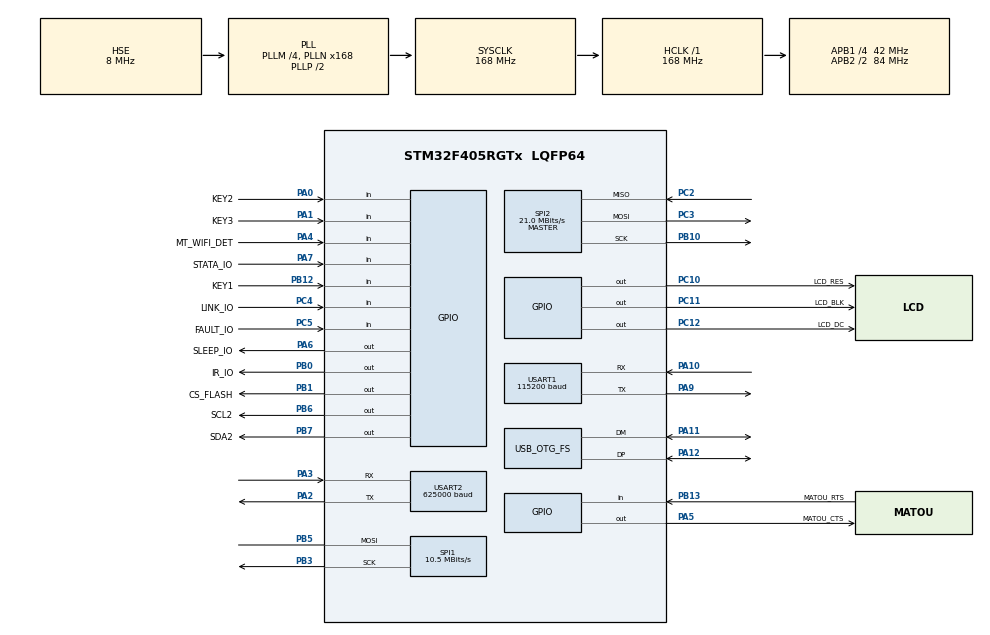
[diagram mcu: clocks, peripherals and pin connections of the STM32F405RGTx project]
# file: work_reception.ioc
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Dma.Request0=USART1_TX
Dma.Request1=USART2_TX
Dma.USART1_TX.0.Direction=DMA_MEMORY_TO_PERIPH
Dma.USART1_TX.0.FIFOMode=DMA_FIFOMODE_DISABLE
Dma.USART1_TX.0.Instance=DMA2_Stream7
Dma.USART1_TX.0.MemDataAlignment=DMA_MDATAALIGN_BYTE
Dma.USART1_TX.0.MemInc=DMA_MINC_ENABLE
Dma.USART1_TX.0.Mode=DMA_NORMAL
Dma.USART1_TX.0.PeriphDataAlignment=DMA_PDATAALIGN_BYTE
Dma.USART1_TX.0.PeriphInc=DMA_PINC_DISABLE
Dma.USART1_TX.0.Priority=DMA_PRIORITY_HIGH
Dma.USART2_TX.1.Direction=DMA_MEMORY_TO_PERIPH
Dma.USART2_TX.1.FIFOMode=DMA_FIFOMODE_DISABLE
Dma.USART2_TX.1.Instance=DMA1_Stream6
Dma.USART2_TX.1.MemDataAlignment=DMA_MDATAALIGN_BYTE
Dma.USART2_TX.1.MemInc=DMA_MINC_ENABLE
Dma.USART2_TX.1.Mode=DMA_NORMAL
Dma.USART2_TX.1.PeriphDataAlignment=DMA_PDATAALIGN_BYTE
Dma.USART2_TX.1.PeriphInc=DMA_PINC_DISABLE
Dma.USART2_TX.1.Priority=DMA_PRIORITY_LOW
FREERTOS.Tasks01=defaultTask,0,5000,StartDefaultTask,Default,NULL,Dynamic,NULL,NULL;FramSaveTask,-3,128,framSaveTaskFun,Default,NULL,Dynamic,NULL,NULL;CommunicationTa,-3,128,communicationTaskFun,Default,NULL,Dynamic,NULL,NULL
FREERTOS.configTOTAL_HEAP_SIZE=30000
Mcu.Family=STM32F4
Mcu.Name=STM32F405RGTx
Mcu.Package=LQFP64
NVIC.DMA1_Stream6_IRQn=true\:5\:0\:false\:false\:true\:true\:false\:true\:true
NVIC.DMA2_Stream7_IRQn=true\:5\:0\:false\:false\:true\:true\:false\:true\:true
NVIC.OTG_FS_IRQn=true\:5\:0\:false\:false\:true\:true\:true\:true\:true
NVIC.PriorityGroup=NVIC_PRIORITYGROUP_4
NVIC.RTC_Alarm_IRQn=true\:5\:0\:false\:false\:true\:true\:true\:true\:true
NVIC.TIM1_UP_TIM10_IRQn=true\:5\:0\:false\:false\:true\:true\:true\:true\:true
NVIC.TIM4_IRQn=true\:5\:0\:false\:false\:true\:true\:true\:true\:true
NVIC.TIM6_DAC_IRQn=true\:5\:0\:true\:false\:true\:true\:true\:true\:true
NVIC.TIM7_IRQn=true\:5\:0\:true\:false\:true\:true\:true\:true\:true
NVIC.TIM8_TRG_COM_TIM14_IRQn=true\:15\:0\:false\:false\:true\:false\:false\:true\:true
NVIC.TimeBase=TIM8_TRG_COM_TIM14_IRQn
NVIC.TimeBaseIP=TIM14
NVIC.USART1_IRQn=true\:5\:0\:false\:false\:true\:true\:true\:true\:true
NVIC.USART2_IRQn=true\:5\:0\:false\:false\:true\:true\:true\:true\:true
PA0-WKUP.GPIO_Label=KEY2
PA0-WKUP.GPIO_PuPd=GPIO_PULLUP
PA0-WKUP.Signal=GPIO_Input
PA1.GPIO_Label=KEY3
PA1.GPIO_PuPd=GPIO_PULLUP
PA1.Signal=GPIO_Input
PA10.Mode=Asynchronous
PA10.Signal=USART1_RX
PA11.Mode=Device_Only
PA11.Signal=USB_OTG_FS_DM
PA12.Mode=Device_Only
PA12.Signal=USB_OTG_FS_DP
PA13.Mode=Serial_Wire
PA13.Signal=SYS_JTMS-SWDIO
PA14.Mode=Serial_Wire
PA14.Signal=SYS_JTCK-SWCLK
PA2.Mode=Asynchronous
PA2.Signal=USART2_TX
PA3.Mode=Asynchronous
PA3.Signal=USART2_RX
PA4.GPIO_Label=MT_WIFI_DET
PA4.Signal=GPIO_Input
PA5.GPIO_Label=MATOU_CTS
PA5.Signal=GPIO_Output
PA6.GPIO_Label=SLEEP_IO
PA6.Signal=GPIO_Output
PA7.GPIO_Label=STATA_IO
PA7.Signal=GPIO_Input
PA9.Mode=Asynchronous
PA9.Signal=USART1_TX
PB0.GPIO_Label=IR_IO
PB0.Signal=GPIO_Output
PB1.GPIO_Label=CS_FLASH
PB1.Signal=GPIO_Output
PB10.Mode=Full_Duplex_Master
PB10.Signal=SPI2_SCK
PB12.GPIO_Label=KEY1
PB12.GPIO_PuPd=GPIO_PULLUP
PB12.Signal=GPIO_Input
PB13.GPIO_Label=MATOU_RTS
PB13.Signal=GPIO_Input
PB3.Mode=Simplex_Bidirectional_Master
PB3.Signal=SPI1_SCK
PB5.Mode=Simplex_Bidirectional_Master
PB5.Signal=SPI1_MOSI
PB6.GPIO_Label=SCL2
PB6.GPIO_PuPd=GPIO_PULLUP
PB6.GPIO_Speed=GPIO_SPEED_FREQ_VERY_HIGH
PB6.PinState=GPIO_PIN_SET
PB6.Signal=GPIO_Output
PB7.GPIO_Label=SDA2
PB7.GPIO_PuPd=GPIO_PULLUP
PB7.GPIO_Speed=GPIO_SPEED_FREQ_VERY_HIGH
PB7.PinState=GPIO_PIN_SET
PB7.Signal=GPIO_Output
PC10.GPIO_Label=LCD_RES
PC10.Signal=GPIO_Output
PC11.GPIO_Label=LCD_BLK
PC11.Signal=GPIO_Output
PC12.GPIO_Label=LCD_DC
PC12.Signal=GPIO_Output
PC14-OSC32_IN.Mode=LSE-External-Oscillator
PC14-OSC32_IN.Signal=RCC_OSC32_IN
PC15-OSC32_OUT.Mode=LSE-External-Oscillator
PC15-OSC32_OUT.Signal=RCC_OSC32_OUT
PC2.Mode=Full_Duplex_Master
PC2.Signal=SPI2_MISO
PC3.Mode=Full_Duplex_Master
PC3.Signal=SPI2_MOSI
PC4.GPIO_Label=LINK_IO
PC4.Signal=GPIO_Input
PC5.GPIO_Label=FAULT_IO
PC5.Signal=GPIO_Input
PH0-OSC_IN.Mode=HSE-External-Oscillator
PH0-OSC_IN.Signal=RCC_OSC_IN
PH1-OSC_OUT.Mode=HSE-External-Oscillator
PH1-OSC_OUT.Signal=RCC_OSC_OUT
ProjectManager.HeapSize=0x200
ProjectManager.StackSize=0x400
ProjectManager.TargetToolchain=STM32CubeIDE
RCC.48MHZClocksFreq_Value=48000000
RCC.AHBFreq_Value=168000000
RCC.APB1CLKDivider=RCC_HCLK_DIV4
RCC.APB1Freq_Value=42000000
RCC.APB1TimFreq_Value=84000000
RCC.APB2CLKDivider=RCC_HCLK_DIV2
RCC.APB2Freq_Value=84000000
RCC.APB2TimFreq_Value=168000000
RCC.CortexFreq_Value=168000000
RCC.HCLKFreq_Value=168000000
RCC.HSE_VALUE=8000000
RCC.HSI_VALUE=16000000
RCC.PLLM=4
RCC.PLLN=168
RCC.PLLQ=7
RCC.RCC_RTC_Clock_Source=RCC_RTCCLKSOURCE_LSE
RCC.RCC_RTC_Clock_SourceVirtual=RCC_RTCCLKSOURCE_LSE
RCC.SYSCLKFreq_VALUE=168000000
RCC.SYSCLKSource=RCC_SYSCLKSOURCE_PLLCLK
RCC.VCOOutputFreq_Value=336000000
RTC.Alarm=RTC_ALARM_A
RTC.Format=RTC_FORMAT_BCD
RTC.Hours=1
RTC.Minutes=20
RTC.Month=RTC_MONTH_MARCH
RTC.Seconds=30
RTC.WeekDay=RTC_WEEKDAY_SUNDAY
RTC.Year=10
SPI1.BaudRatePrescaler=SPI_BAUDRATEPRESCALER_8
SPI1.CalculateBaudRate=10.5 MBits/s
SPI1.Direction=SPI_DIRECTION_1LINE
SPI1.Mode=SPI_MODE_MASTER
SPI1.VirtualType=VM_MASTER
SPI2.BaudRatePrescaler=SPI_BAUDRATEPRESCALER_2
SPI2.CalculateBaudRate=21.0 MBits/s
SPI2.Direction=SPI_DIRECTION_2LINES
SPI2.Mode=SPI_MODE_MASTER
SPI2.VirtualType=VM_MASTER
TIM10.Period=100-1
TIM10.Prescaler=840-1
TIM4.Period=1000-1
TIM4.Prescaler=42-1
TIM6.Period=100-1
TIM6.Prescaler=8400-1
TIM7.Period=500-1
TIM7.Prescaler=84-1
USART1.BaudRate=115200
USART1.StopBits=STOPBITS_1
USART1.VirtualMode=VM_ASYNC
USART2.BaudRate=625000
USART2.VirtualMode=VM_ASYNC
USB_DEVICE.CLASS_NAME_FS=CUSTOM_HID
USB_DEVICE.CUSTOM_HID_FS_BINTERVAL=0x1
USB_DEVICE.PRODUCT_STRING_CUSTOMHID_FS=torque
USB_DEVICE.USBD_CUSTOMHID_OUTREPORT_BUF_SIZE-CUSTOM_HID_FS=64
USB_DEVICE.USBD_CUSTOM_HID_REPORT_DESC_SIZE-CUSTOM_HID_FS=52
USB_DEVICE.VID-CUSTOM_HID_FS=1672
USB_DEVICE.VirtualMode-CUSTOM_HID_FS=CustomHid
USB_DEVICE.VirtualModeFS=Custom_Hid_FS
USB_OTG_FS.VirtualMode=Device_Only
VP_FREERTOS_VS_CMSIS_V1.Mode=CMSIS_V1
VP_RTC_VS_RTC_Activate.Mode=RTC_Enabled
VP_RTC_VS_RTC_Alarm_A_Intern.Mode=Alarm A
VP_RTC_VS_RTC_Calendar.Mode=RTC_Calendar
VP_SYS_VS_tim14.Mode=TIM14
VP_TIM10_VS_ClockSourceINT.Mode=Enable_Timer
VP_TIM4_VS_ClockSourceINT.Mode=Internal
VP_TIM6_VS_ClockSourceINT.Mode=Enable_Timer
VP_TIM7_VS_ClockSourceINT.Mode=Enable_Timer
VP_USB_DEVICE_VS_USB_DEVICE_CUSTOM_HID_FS.Mode=CUSTOM_HID_FS
board=custom

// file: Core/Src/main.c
/* USER CODE BEGIN Header */
/**
  ******************************************************************************
  * @file           : main.c
  * @brief          : Main program body
  ******************************************************************************
  * @attention
  *
  * Copyright (c) 2026 STMicroelectronics.
  * All rights reserved.
  *
  * This software is licensed under terms that can be found in the LICENSE file
  * in the root directory of this software component.
  * If no LICENSE file comes with this software, it is provided AS-IS.
  *
  ******************************************************************************
  */
/* USER CODE END Header */
#include "main.h"
#include "cmsis_os.h"
#include "dma.h"
#include "rtc.h"
#include "spi.h"
#include "tim.h"
#include "usart.h"
#include "usb_device.h"
#include "gpio.h"

void SystemClock_Config(void);
void MX_FREERTOS_Init(void);

int main(void)
{

  /* MCU Configuration--------------------------------------------------------*/

  /* Reset of all peripherals, Initializes the Flash interface and the Systick. */
  HAL_Init();

  /* Configure the system clock */
  SystemClock_Config();

  /* Initialize all configured peripherals */
  MX_GPIO_Init();
  MX_DMA_Init();
  MX_TIM7_Init();
  MX_TIM6_Init();
  MX_USART2_UART_Init();
  MX_USART1_UART_Init();
  MX_SPI1_Init();
  MX_RTC_Init();
  MX_SPI2_Init();
  MX_TIM4_Init();
  MX_TIM10_Init();
  /* USER CODE BEGIN 2 */
  HAL_TIM_Base_Start_IT(&htim10);
  /* USER CODE END 2 */

  /* Call init function for freertos objects (in cmsis_os2.c) */
  MX_FREERTOS_Init();

  /* Start scheduler */
  osKernelStart();

  /* We should never get here as control is now taken by the scheduler */

  /* Infinite loop */
  while (1)
  {

  }
}

void SystemClock_Config(void)
{
  RCC_OscInitTypeDef RCC_OscInitStruct = {0};
  RCC_ClkInitTypeDef RCC_ClkInitStruct = {0};

  /** Configure the main internal regulator output voltage
  */
  __HAL_RCC_PWR_CLK_ENABLE();
  __HAL_PWR_VOLTAGESCALING_CONFIG(PWR_REGULATOR_VOLTAGE_SCALE1);

  /** Initializes the RCC Oscillators according to the specified parameters
  * in the RCC_OscInitTypeDef structure.
  */
  RCC_OscInitStruct.OscillatorType = RCC_OSCILLATORTYPE_HSE|RCC_OSCILLATORTYPE_LSE;
  RCC_OscInitStruct.HSEState = RCC_HSE_ON;
  RCC_OscInitStruct.LSEState = RCC_LSE_ON;
  RCC_OscInitStruct.PLL.PLLState = RCC_PLL_ON;
  RCC_OscInitStruct.PLL.PLLSource = RCC_PLLSOURCE_HSE;
  RCC_OscInitStruct.PLL.PLLM = 4;
  RCC_OscInitStruct.PLL.PLLN = 168;
  RCC_OscInitStruct.PLL.PLLP = RCC_PLLP_DIV2;
  RCC_OscInitStruct.PLL.PLLQ = 7;
  if (HAL_RCC_OscConfig(&RCC_OscInitStruct) != HAL_OK)
  {
    Error_Handler();
  }

  /** Initializes the CPU, AHB and APB buses clocks
  */
  RCC_ClkInitStruct.ClockType = RCC_CLOCKTYPE_HCLK|RCC_CLOCKTYPE_SYSCLK
                              |RCC_CLOCKTYPE_PCLK1|RCC_CLOCKTYPE_PCLK2;
  RCC_ClkInitStruct.SYSCLKSource = RCC_SYSCLKSOURCE_PLLCLK;
  RCC_ClkInitStruct.AHBCLKDivider = RCC_SYSCLK_DIV1;
  RCC_ClkInitStruct.APB1CLKDivider = RCC_HCLK_DIV4;
  RCC_ClkInitStruct.APB2CLKDivider = RCC_HCLK_DIV2;

  if (HAL_RCC_ClockConfig(&RCC_ClkInitStruct, FLASH_LATENCY_5) != HAL_OK)
  {
    Error_Handler();
  }
}

//void HAL_TIM_PeriodElapsedCallback(TIM_HandleTypeDef *htim)
//{
//  /* USER CODE BEGIN Callback 0 */
//
//  /* USER CODE END Callback 0 */
//  if (htim->Instance == TIM14) {
//    HAL_IncTick();
//  }
//  /* USER CODE BEGIN Callback 1 */
//
//  /* USER CODE END Callback 1 */
//}

void Error_Handler(void)
{
  __disable_irq();
  while (1)
  {
  }
}

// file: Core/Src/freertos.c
/* USER CODE BEGIN Header */
/**
  ******************************************************************************
  * File Name          : freertos.c
  * Description        : Code for freertos applications
  ******************************************************************************
  * @attention
  *
  * Copyright (c) 2026 STMicroelectronics.
  * All rights reserved.
  *
  * This software is licensed under terms that can be found in the LICENSE file
  * in the root directory of this software component.
  * If no LICENSE file comes with this software, it is provided AS-IS.
  *
  ******************************************************************************
  */
/* USER CODE END Header */

#include "FreeRTOS.h"
#include "task.h"
#include "main.h"
#include "cmsis_os.h"

osThreadId defaultTaskHandle;
osThreadId FramSaveTaskHandle;
osThreadId CommunicationTaHandle;

void StartDefaultTask(void const * argument);
void framSaveTaskFun(void const * argument);
void communicationTaskFun(void const * argument);

extern void MX_USB_DEVICE_Init(void);
void MX_FREERTOS_Init(void); /* (MISRA C 2004 rule 8.1) */

/* GetIdleTaskMemory prototype (linked to static allocation support) */
void vApplicationGetIdleTaskMemory( StaticTask_t **ppxIdleTaskTCBBuffer, StackType_t **ppxIdleTaskStackBuffer, uint32_t *pulIdleTaskStackSize );

/* USER CODE BEGIN GET_IDLE_TASK_MEMORY */
static StaticTask_t xIdleTaskTCBBuffer;
static StackType_t xIdleStack[configMINIMAL_STACK_SIZE];

void vApplicationGetIdleTaskMemory( StaticTask_t **ppxIdleTaskTCBBuffer, StackType_t **ppxIdleTaskStackBuffer, uint32_t *pulIdleTaskStackSize )
{
  *ppxIdleTaskTCBBuffer = &xIdleTaskTCBBuffer;
  *ppxIdleTaskStackBuffer = &xIdleStack[0];
  *pulIdleTaskStackSize = configMINIMAL_STACK_SIZE;
  /* place for user code */
}
/* USER CODE END GET_IDLE_TASK_MEMORY */

void MX_FREERTOS_Init(void) {

  /* Create the thread(s) */
  /* definition and creation of defaultTask */
//  osThreadDef(defaultTask, StartDefaultTask, osPriorityNormal, 0, 5000);
//  defaultTaskHandle = osThreadCreate(osThread(defaultTask), NULL);
//
//  /* definition and creation of FramSaveTask */
//  osThreadDef(FramSaveTask, framSaveTaskFun, osPriorityIdle, 0, 128);
//  FramSaveTaskHandle = osThreadCreate(osThread(FramSaveTask), NULL);
//
//  /* definition and creation of CommunicationTa */
//  osThreadDef(CommunicationTa, communicationTaskFun, osPriorityIdle, 0, 128);
//  CommunicationTaHandle = osThreadCreate(osThread(CommunicationTa), NULL);

  /* USER CODE BEGIN RTOS_THREADS */
  MX_USB_DEVICE_Init();
  app_task_create();
  /* USER CODE END RTOS_THREADS */

}

void StartDefaultTask(void const * argument)
{
  /* init code for USB_DEVICE */
  MX_USB_DEVICE_Init();
  /* USER CODE BEGIN StartDefaultTask */
  /* Infinite loop */
  for(;;)
  {
    osDelay(10);
  }
  /* USER CODE END StartDefaultTask */
}

void framSaveTaskFun(void const * argument)
{
  for(;;)
  {
    osDelay(1);
  }
}

void communicationTaskFun(void const * argument)
{
  for(;;)
  {
  }
}
